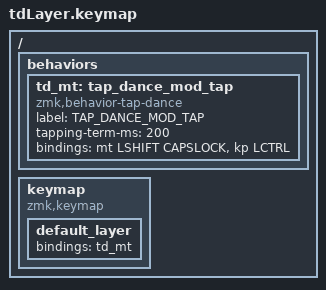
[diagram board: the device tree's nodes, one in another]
#include <behaviors.dtsi>
#include <dt-bindings/zmk/keys.h>

/ {
    behaviors {
        td_mt: tap_dance_mod_tap {
            compatible = "zmk,behavior-tap-dance";
            label = "TAP_DANCE_MOD_TAP";
            #binding-cells = <0>;
            tapping-term-ms = <200>;
            bindings = <&mt LSHIFT CAPSLOCK>, <&kp LCTRL>;
        };
    };

    keymap {
        compatible = "zmk,keymap";

        default_layer {
            bindings = <
                &td_mt
            >;
        };
    };
};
